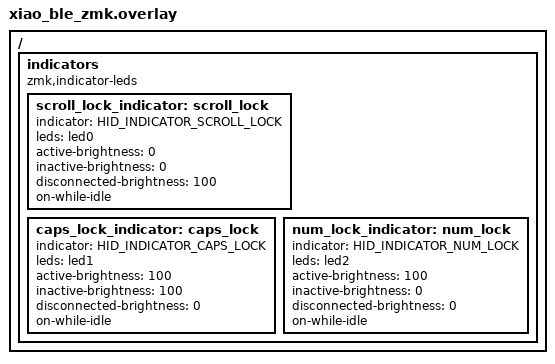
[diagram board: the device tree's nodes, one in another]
#include <dt-bindings/zmk/hid_indicators.h>

/ {
    indicators {
        compatible = "zmk,indicator-leds";

        /* Red LED near USB: on when not connected to a host */
        scroll_lock_indicator: scroll_lock {
            indicator = <HID_INDICATOR_SCROLL_LOCK>;
            leds = <&led0>;
        };

        /* Green LED near USB: on when connected to a host */
        caps_lock_indicator: caps_lock {
            indicator = <HID_INDICATOR_CAPS_LOCK>;
            leds = <&led1>;
        };

        /* Blue LED near USB: reserved for future use / caps/num/scroll state */
        num_lock_indicator: num_lock {
            indicator = <HID_INDICATOR_NUM_LOCK>;
            leds = <&led2>;
        };
    };
};

&scroll_lock_indicator {
    active-brightness = <0>;
    inactive-brightness = <0>;
    disconnected-brightness = <100>;
    on-while-idle;
};

&caps_lock_indicator {
    active-brightness = <100>;
    inactive-brightness = <100>;
    disconnected-brightness = <0>;
    on-while-idle;
};

&num_lock_indicator {
    active-brightness = <100>;
    inactive-brightness = <0>;
    disconnected-brightness = <0>;
    on-while-idle;
};
